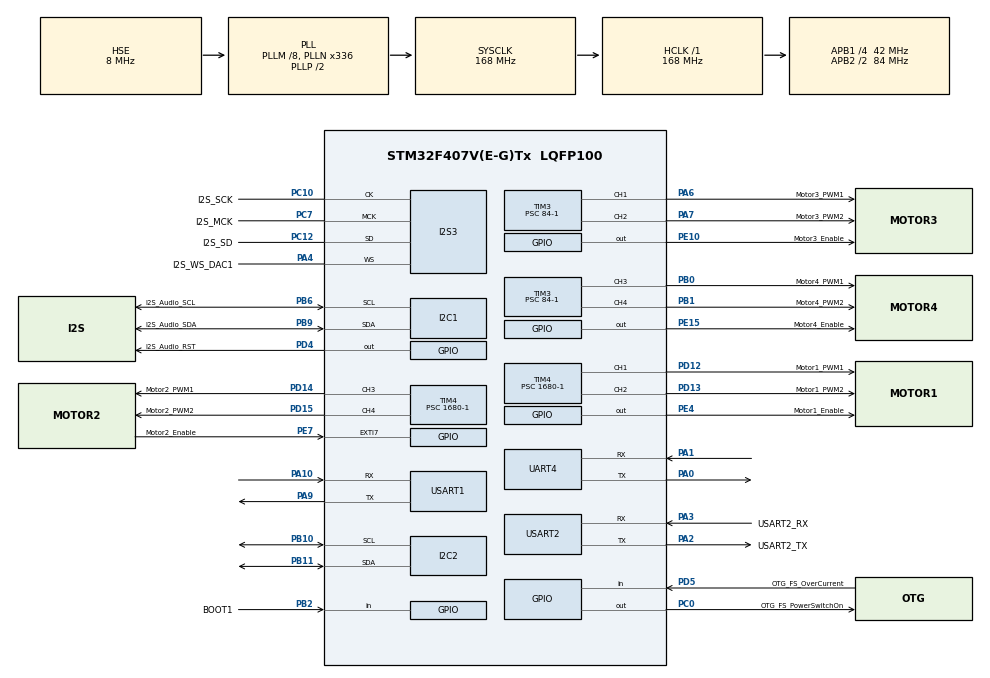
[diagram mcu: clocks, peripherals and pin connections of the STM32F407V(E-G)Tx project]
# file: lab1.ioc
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I2S3.AudioFreq-Half_Duplex_Master=I2S_AUDIOFREQ_96K
I2S3.ErrorAudioFreq=-2.34 %
I2S3.ErrorAudioFreq-Half_Duplex_Master=0.8 %
I2S3.FullDuplexMode=I2S_FULLDUPLEXMODE_DISABLE
I2S3.Instance=SPI$Index
I2S3.RealAudioFreq=93.75 KHz
I2S3.RealAudioFreq-Half_Duplex_Master=96.774 KHz
I2S3.VirtualMode=I2S_MODE_MASTER
Mcu.Family=STM32F4
Mcu.Name=STM32F407V(E-G)Tx
Mcu.Package=LQFP100
NVIC.PriorityGroup=NVIC_PRIORITYGROUP_0
NVIC.UART4_IRQn=true\:0\:0\:false\:false\:true\:true\:true\:true
PA0-WKUP.Mode=Asynchronous
PA0-WKUP.Signal=UART4_TX
PA1.Mode=Asynchronous
PA1.Signal=UART4_RX
PA10.Mode=Asynchronous
PA10.Signal=USART1_RX
PA13.GPIO_Label=SWDIO
PA13.Mode=Serial_Wire
PA13.Signal=SYS_JTMS-SWDIO
PA14.GPIO_Label=SWCLK
PA14.Mode=Serial_Wire
PA14.Signal=SYS_JTCK-SWCLK
PA2.GPIO_Label=USART2_TX
PA2.Mode=Asynchronous
PA2.Signal=USART2_TX
PA3.GPIO_Label=USART2_RX
PA3.Mode=Asynchronous
PA3.Signal=USART2_RX
PA4.GPIO_Label=I2S_WS_DAC1
PA4.GPIO_Mode=GPIO_MODE_AF_PP
PA4.GPIO_PuPd=GPIO_NOPULL
PA4.GPIO_Speed=GPIO_SPEED_FREQ_LOW
PA4.Mode=Half_Duplex_Master
PA4.Signal=I2S3_WS
PA6.GPIO_Label=Motor3_PWM1
PA6.Signal=S_TIM3_CH1
PA7.GPIO_Label=Motor3_PWM2
PA7.Signal=S_TIM3_CH2
PA9.Mode=Asynchronous
PA9.Signal=USART1_TX
PB0.GPIO_Label=Motor4_PWM1
PB0.Signal=S_TIM3_CH3
PB1.GPIO_Label=Motor4_PWM2
PB1.Signal=S_TIM3_CH4
PB10.Mode=I2C
PB10.Signal=I2C2_SCL
PB11.Mode=I2C
PB11.Signal=I2C2_SDA
PB2.GPIO_Label=BOOT1
PB2.GPIO_Mode=GPIO_MODE_INPUT
PB2.GPIO_PuPd=GPIO_NOPULL
PB2.Signal=GPIO_Input
PB6.GPIO_Label=I2S_Audio_SCL
PB6.GPIO_Mode=GPIO_MODE_AF_OD
PB6.GPIO_Pu=GPIO_PULLUP
PB6.GPIO_PuPd=GPIO_NOPULL
PB6.GPIO_Speed=GPIO_SPEED_FREQ_LOW
PB6.Mode=I2C
PB6.Signal=I2C1_SCL
PB9.GPIO_Label=I2S_Audio_SDA
PB9.GPIO_Mode=GPIO_MODE_AF_OD
PB9.GPIO_Pu=GPIO_PULLUP
PB9.GPIO_PuPd=GPIO_NOPULL
PB9.GPIO_Speed=GPIO_SPEED_FREQ_LOW
PB9.Mode=I2C
PB9.Signal=I2C1_SDA
PC0.GPIO_Label=OTG_FS_PowerSwitchOn
PC0.GPIO_PuPd=GPIO_NOPULL
PC0.GPIO_Speed=GPIO_SPEED_FREQ_LOW
PC0.PinState=GPIO_PIN_SET
PC0.Signal=GPIO_Output
PC10.GPIO_Label=I2S_SCK
PC10.GPIO_Mode=GPIO_MODE_AF_PP
PC10.GPIO_PuPd=GPIO_NOPULL
PC10.GPIO_Speed=GPIO_SPEED_FREQ_LOW
PC10.Mode=Half_Duplex_Master
PC10.Signal=I2S3_CK
PC12.GPIO_Label=I2S_SD
PC12.GPIO_Mode=GPIO_MODE_AF_PP
PC12.GPIO_PuPd=GPIO_NOPULL
PC12.GPIO_Speed=GPIO_SPEED_FREQ_LOW
PC12.Mode=Half_Duplex_Master
PC12.Signal=I2S3_SD
PC14-OSC32_IN.GPIO_Label=PC14-OSC32_IN
PC14-OSC32_IN.Mode=LSE-External-Oscillator
PC14-OSC32_IN.Signal=RCC_OSC32_IN
PC15-OSC32_OUT.GPIO_Label=PC15-OSC32_OUT
PC15-OSC32_OUT.Mode=LSE-External-Oscillator
PC15-OSC32_OUT.Signal=RCC_OSC32_OUT
PC7.GPIO_Label=I2S_MCK
PC7.GPIO_Mode=GPIO_MODE_AF_PP
PC7.GPIO_PuPd=GPIO_NOPULL
PC7.GPIO_Speed=GPIO_SPEED_FREQ_LOW
PC7.Mode=Master_Clock_Activated
PC7.Signal=I2S3_MCK
PD12.GPIO_Label=Motor1_PWM1
PD12.Signal=S_TIM4_CH1
PD13.GPIO_Label=Motor1_PWM2
PD13.Signal=S_TIM4_CH2
PD14.GPIO_Label=Motor2_PWM1
PD14.Signal=S_TIM4_CH3
PD15.GPIO_Label=Motor2_PWM2
PD15.Signal=S_TIM4_CH4
PD4.GPIO_Label=I2S_Audio_RST
PD4.GPIO_PuPd=GPIO_NOPULL
PD4.GPIO_Speed=GPIO_SPEED_FREQ_LOW
PD4.Signal=GPIO_Output
PD5.GPIO_Label=OTG_FS_OverCurrent
PD5.GPIO_Mode=GPIO_MODE_INPUT
PD5.GPIO_PuPd=GPIO_NOPULL
PD5.Signal=GPIO_Input
PE10.GPIO_Label=Motor3_Enable
PE10.Signal=GPIO_Output
PE15.GPIO_Label=Motor4_Enable
PE15.Signal=GPIO_Output
PE4.GPIO_Label=Motor1_Enable
PE4.Signal=GPIO_Output
PE7.GPIO_Label=Motor2_Enable
PE7.Signal=GPXTI7
PH0-OSC_IN.GPIO_Label=PH0-OSC_IN
PH0-OSC_IN.Mode=HSE-External-Oscillator
PH0-OSC_IN.Signal=RCC_OSC_IN
PH1-OSC_OUT.GPIO_Label=PH1-OSC_OUT
PH1-OSC_OUT.Mode=HSE-External-Oscillator
PH1-OSC_OUT.Signal=RCC_OSC_OUT
ProjectManager.HeapSize=0x200
ProjectManager.StackSize=0x400
ProjectManager.TargetToolchain=STM32CubeIDE
RCC.48MHZClocksFreq_Value=48000000
RCC.AHBFreq_Value=168000000
RCC.APB1CLKDivider=RCC_HCLK_DIV4
RCC.APB1Freq_Value=42000000
RCC.APB1TimFreq_Value=84000000
RCC.APB2CLKDivider=RCC_HCLK_DIV2
RCC.APB2Freq_Value=84000000
RCC.APB2TimFreq_Value=168000000
RCC.CortexFreq_Value=168000000
RCC.HCLKFreq_Value=168000000
RCC.HSE_VALUE=8000000
RCC.HSI_VALUE=16000000
RCC.PLLM=8
RCC.PLLN=336
RCC.PLLQ=7
RCC.PLLSourceVirtual=RCC_PLLSOURCE_HSE
RCC.SYSCLKFreq_VALUE=168000000
RCC.SYSCLKSource=RCC_SYSCLKSOURCE_PLLCLK
RCC.VCOOutputFreq_Value=336000000
SH.S_TIM3_CH1.0=TIM3_CH1,PWM Generation1 CH1
SH.S_TIM3_CH2.0=TIM3_CH2,PWM Generation2 CH2
SH.S_TIM3_CH3.0=TIM3_CH3,PWM Generation3 CH3
SH.S_TIM3_CH4.0=TIM3_CH4,PWM Generation4 CH4
SH.S_TIM4_CH1.0=TIM4_CH1,PWM Generation1 CH1
SH.S_TIM4_CH2.0=TIM4_CH2,PWM Generation2 CH2
SH.S_TIM4_CH3.0=TIM4_CH3,PWM Generation3 CH3
SH.S_TIM4_CH4.0=TIM4_CH4,PWM Generation4 CH4
TIM3.Channel-PWM\ Generation1\ CH1=TIM_CHANNEL_1
TIM3.Channel-PWM\ Generation2\ CH2=TIM_CHANNEL_2
TIM3.Channel-PWM\ Generation3\ CH3=TIM_CHANNEL_3
TIM3.Channel-PWM\ Generation4\ CH4=TIM_CHANNEL_4
TIM3.Period=100-1
TIM3.Prescaler=84-1
TIM4.Channel-PWM\ Generation1\ CH1=TIM_CHANNEL_1
TIM4.Channel-PWM\ Generation2\ CH2=TIM_CHANNEL_2
TIM4.Channel-PWM\ Generation3\ CH3=TIM_CHANNEL_3
TIM4.Channel-PWM\ Generation4\ CH4=TIM_CHANNEL_4
TIM4.Period=1000-1
TIM4.Prescaler=1680-1
UART4.VirtualMode=Asynchronous
USART1.VirtualMode=VM_ASYNC
USART2.VirtualMode=VM_ASYNC
VP_TIM3_VS_ClockSourceINT.Mode=Internal
VP_TIM4_VS_ClockSourceINT.Mode=Internal
board=STM32F407G-DISC1

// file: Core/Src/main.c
/* USER CODE BEGIN Header */
/**
  ******************************************************************************
  * @file           : main.c
  * @brief          : Main program body
  ******************************************************************************
  * @attention
  *
  * Copyright (c) 2023 STMicroelectronics.
  * All rights reserved.
  *
  * This software is licensed under terms that can be found in the LICENSE file
  * in the root directory of this software component.
  * If no LICENSE file comes with this software, it is provided AS-IS.
  *
  ******************************************************************************
  */
/* USER CODE END Header */
#include "main.h"

I2C_HandleTypeDef hi2c1;
I2C_HandleTypeDef hi2c2;

I2S_HandleTypeDef hi2s3;

TIM_HandleTypeDef htim3;
TIM_HandleTypeDef htim4;

UART_HandleTypeDef huart4;
UART_HandleTypeDef huart1;
UART_HandleTypeDef huart2;

void SystemClock_Config(void);
static void MX_GPIO_Init(void);
static void MX_I2C1_Init(void);
static void MX_I2S3_Init(void);
static void MX_I2C2_Init(void);
static void MX_TIM3_Init(void);
static void MX_TIM4_Init(void);
static void MX_UART4_Init(void);
static void MX_USART1_UART_Init(void);
static void MX_USART2_UART_Init(void);

int main(void)
{

  /* MCU Configuration--------------------------------------------------------*/

  /* Reset of all peripherals, Initializes the Flash interface and the Systick. */
  HAL_Init();

  /* Configure the system clock */
  SystemClock_Config();

  /* Initialize all configured peripherals */
  MX_GPIO_Init();
  MX_I2C1_Init();
  MX_I2S3_Init();
  MX_I2C2_Init();
  MX_TIM3_Init();
  MX_TIM4_Init();
  MX_UART4_Init();
  MX_USART1_UART_Init();
  MX_USART2_UART_Init();
  /* USER CODE BEGIN 2 */
  // Motor Enable Pins set to LOW
  HAL_GPIO_WritePin(Motor1_Enable_GPIO_Port, Motor1_Enable_Pin, GPIO_PIN_SET);
  HAL_GPIO_WritePin(Motor2_Enable_GPIO_Port, Motor2_Enable_Pin, GPIO_PIN_SET);
  /*
  HAL_GPIO_WritePin(Motor3_Enable_GPIO_Port, Motor3_Enable_Pin, GPIO_PIN_SET);
  HAL_GPIO_WritePin(Motor4_Enable_GPIO_Port, Motor4_Enable_Pin, GPIO_PIN_SET);
  */

  // PWM Settings for Motors PWM1 & PWM2 pins
  /*
  TIM3->CCR1 = 0;
  TIM3->CCR2 = 0;
  TIM3->CCR3 = 0;
  TIM3->CCR4 = 0;
  */

  TIM4->CCR1 = 0;
  TIM4->CCR2 = 0;
  TIM4->CCR3 = 0;
  TIM4->CCR4 = 0;

  // PWM Signals is started
  /*
  HAL_TIM_PWM_Start(&htim3, TIM_CHANNEL_1);
  HAL_TIM_PWM_Start(&htim3, TIM_CHANNEL_2);
  HAL_TIM_PWM_Start(&htim3, TIM_CHANNEL_3);
  HAL_TIM_PWM_Start(&htim3, TIM_CHANNEL_4);
  */

  HAL_TIM_PWM_Start(&htim4, TIM_CHANNEL_1);
  HAL_TIM_PWM_Start(&htim4, TIM_CHANNEL_2);
  HAL_TIM_PWM_Start(&htim4, TIM_CHANNEL_3);
  HAL_TIM_PWM_Start(&htim4, TIM_CHANNEL_4);

  // Enable the UART2 RX Interrupt
  __HAL_UART_ENABLE_IT(&huart4, UART_IT_RXNE);	// Enabled UART RX Interrupt
  /* USER CODE END 2 */

  /* Infinite loop */
  while (1)
  {

  }
}

void SystemClock_Config(void)
{
  RCC_OscInitTypeDef RCC_OscInitStruct = {0};
  RCC_ClkInitTypeDef RCC_ClkInitStruct = {0};

  /** Configure the main internal regulator output voltage
  */
  __HAL_RCC_PWR_CLK_ENABLE();
  __HAL_PWR_VOLTAGESCALING_CONFIG(PWR_REGULATOR_VOLTAGE_SCALE1);

  /** Initializes the RCC Oscillators according to the specified parameters
  * in the RCC_OscInitTypeDef structure.
  */
  RCC_OscInitStruct.OscillatorType = RCC_OSCILLATORTYPE_HSE;
  RCC_OscInitStruct.HSEState = RCC_HSE_ON;
  RCC_OscInitStruct.PLL.PLLState = RCC_PLL_ON;
  RCC_OscInitStruct.PLL.PLLSource = RCC_PLLSOURCE_HSE;
  RCC_OscInitStruct.PLL.PLLM = 8;
  RCC_OscInitStruct.PLL.PLLN = 336;
  RCC_OscInitStruct.PLL.PLLP = RCC_PLLP_DIV2;
  RCC_OscInitStruct.PLL.PLLQ = 7;
  if (HAL_RCC_OscConfig(&RCC_OscInitStruct) != HAL_OK)
  {
    Error_Handler();
  }

  /** Initializes the CPU, AHB and APB buses clocks
  */
  RCC_ClkInitStruct.ClockType = RCC_CLOCKTYPE_HCLK|RCC_CLOCKTYPE_SYSCLK
                              |RCC_CLOCKTYPE_PCLK1|RCC_CLOCKTYPE_PCLK2;
  RCC_ClkInitStruct.SYSCLKSource = RCC_SYSCLKSOURCE_PLLCLK;
  RCC_ClkInitStruct.AHBCLKDivider = RCC_SYSCLK_DIV1;
  RCC_ClkInitStruct.APB1CLKDivider = RCC_HCLK_DIV4;
  RCC_ClkInitStruct.APB2CLKDivider = RCC_HCLK_DIV2;

  if (HAL_RCC_ClockConfig(&RCC_ClkInitStruct, FLASH_LATENCY_5) != HAL_OK)
  {
    Error_Handler();
  }
}

static void MX_I2C1_Init(void)
{

  hi2c1.Instance = I2C1;
  hi2c1.Init.ClockSpeed = 100000;
  hi2c1.Init.DutyCycle = I2C_DUTYCYCLE_2;
  hi2c1.Init.OwnAddress1 = 0;
  hi2c1.Init.AddressingMode = I2C_ADDRESSINGMODE_7BIT;
  hi2c1.Init.DualAddressMode = I2C_DUALADDRESS_DISABLE;
  hi2c1.Init.OwnAddress2 = 0;
  hi2c1.Init.GeneralCallMode = I2C_GENERALCALL_DISABLE;
  hi2c1.Init.NoStretchMode = I2C_NOSTRETCH_DISABLE;
  if (HAL_I2C_Init(&hi2c1) != HAL_OK)
  {
    Error_Handler();
  }

}

static void MX_I2C2_Init(void)
{

  hi2c2.Instance = I2C2;
  hi2c2.Init.ClockSpeed = 100000;
  hi2c2.Init.DutyCycle = I2C_DUTYCYCLE_2;
  hi2c2.Init.OwnAddress1 = 0;
  hi2c2.Init.AddressingMode = I2C_ADDRESSINGMODE_7BIT;
  hi2c2.Init.DualAddressMode = I2C_DUALADDRESS_DISABLE;
  hi2c2.Init.OwnAddress2 = 0;
  hi2c2.Init.GeneralCallMode = I2C_GENERALCALL_DISABLE;
  hi2c2.Init.NoStretchMode = I2C_NOSTRETCH_DISABLE;
  if (HAL_I2C_Init(&hi2c2) != HAL_OK)
  {
    Error_Handler();
  }

}

static void MX_I2S3_Init(void)
{

  hi2s3.Instance = SPI3;
  hi2s3.Init.Mode = I2S_MODE_MASTER_TX;
  hi2s3.Init.Standard = I2S_STANDARD_PHILIPS;
  hi2s3.Init.DataFormat = I2S_DATAFORMAT_16B;
  hi2s3.Init.MCLKOutput = I2S_MCLKOUTPUT_ENABLE;
  hi2s3.Init.AudioFreq = I2S_AUDIOFREQ_96K;
  hi2s3.Init.CPOL = I2S_CPOL_LOW;
  hi2s3.Init.ClockSource = I2S_CLOCK_PLL;
  hi2s3.Init.FullDuplexMode = I2S_FULLDUPLEXMODE_DISABLE;
  if (HAL_I2S_Init(&hi2s3) != HAL_OK)
  {
    Error_Handler();
  }

}

static void MX_TIM3_Init(void)
{

  TIM_ClockConfigTypeDef sClockSourceConfig = {0};
  TIM_MasterConfigTypeDef sMasterConfig = {0};
  TIM_OC_InitTypeDef sConfigOC = {0};

  htim3.Instance = TIM3;
  htim3.Init.Prescaler = 84-1;
  htim3.Init.CounterMode = TIM_COUNTERMODE_UP;
  htim3.Init.Period = 100-1;
  htim3.Init.ClockDivision = TIM_CLOCKDIVISION_DIV1;
  htim3.Init.AutoReloadPreload = TIM_AUTORELOAD_PRELOAD_DISABLE;
  if (HAL_TIM_Base_Init(&htim3) != HAL_OK)
  {
    Error_Handler();
  }
  sClockSourceConfig.ClockSource = TIM_CLOCKSOURCE_INTERNAL;
  if (HAL_TIM_ConfigClockSource(&htim3, &sClockSourceConfig) != HAL_OK)
  {
    Error_Handler();
  }
  if (HAL_TIM_PWM_Init(&htim3) != HAL_OK)
  {
    Error_Handler();
  }
  sMasterConfig.MasterOutputTrigger = TIM_TRGO_RESET;
  sMasterConfig.MasterSlaveMode = TIM_MASTERSLAVEMODE_DISABLE;
  if (HAL_TIMEx_MasterConfigSynchronization(&htim3, &sMasterConfig) != HAL_OK)
  {
    Error_Handler();
  }
  sConfigOC.OCMode = TIM_OCMODE_PWM1;
  sConfigOC.Pulse = 0;
  sConfigOC.OCPolarity = TIM_OCPOLARITY_HIGH;
  sConfigOC.OCFastMode = TIM_OCFAST_DISABLE;
  if (HAL_TIM_PWM_ConfigChannel(&htim3, &sConfigOC, TIM_CHANNEL_1) != HAL_OK)
  {
    Error_Handler();
  }
  if (HAL_TIM_PWM_ConfigChannel(&htim3, &sConfigOC, TIM_CHANNEL_2) != HAL_OK)
  {
    Error_Handler();
  }
  if (HAL_TIM_PWM_ConfigChannel(&htim3, &sConfigOC, TIM_CHANNEL_3) != HAL_OK)
  {
    Error_Handler();
  }
  if (HAL_TIM_PWM_ConfigChannel(&htim3, &sConfigOC, TIM_CHANNEL_4) != HAL_OK)
  {
    Error_Handler();
  }
  HAL_TIM_MspPostInit(&htim3);

}

static void MX_TIM4_Init(void)
{

  TIM_ClockConfigTypeDef sClockSourceConfig = {0};
  TIM_MasterConfigTypeDef sMasterConfig = {0};
  TIM_OC_InitTypeDef sConfigOC = {0};

  htim4.Instance = TIM4;
  htim4.Init.Prescaler = 1680-1;
  htim4.Init.CounterMode = TIM_COUNTERMODE_UP;
  htim4.Init.Period = 1000-1;
  htim4.Init.ClockDivision = TIM_CLOCKDIVISION_DIV1;
  htim4.Init.AutoReloadPreload = TIM_AUTORELOAD_PRELOAD_DISABLE;
  if (HAL_TIM_Base_Init(&htim4) != HAL_OK)
  {
    Error_Handler();
  }
  sClockSourceConfig.ClockSource = TIM_CLOCKSOURCE_INTERNAL;
  if (HAL_TIM_ConfigClockSource(&htim4, &sClockSourceConfig) != HAL_OK)
  {
    Error_Handler();
  }
  if (HAL_TIM_PWM_Init(&htim4) != HAL_OK)
  {
    Error_Handler();
  }
  sMasterConfig.MasterOutputTrigger = TIM_TRGO_RESET;
  sMasterConfig.MasterSlaveMode = TIM_MASTERSLAVEMODE_DISABLE;
  if (HAL_TIMEx_MasterConfigSynchronization(&htim4, &sMasterConfig) != HAL_OK)
  {
    Error_Handler();
  }
  sConfigOC.OCMode = TIM_OCMODE_PWM1;
  sConfigOC.Pulse = 0;
  sConfigOC.OCPolarity = TIM_OCPOLARITY_HIGH;
  sConfigOC.OCFastMode = TIM_OCFAST_DISABLE;
  if (HAL_TIM_PWM_ConfigChannel(&htim4, &sConfigOC, TIM_CHANNEL_1) != HAL_OK)
  {
    Error_Handler();
  }
  if (HAL_TIM_PWM_ConfigChannel(&htim4, &sConfigOC, TIM_CHANNEL_2) != HAL_OK)
  {
    Error_Handler();
  }
  if (HAL_TIM_PWM_ConfigChannel(&htim4, &sConfigOC, TIM_CHANNEL_3) != HAL_OK)
  {
    Error_Handler();
  }
  if (HAL_TIM_PWM_ConfigChannel(&htim4, &sConfigOC, TIM_CHANNEL_4) != HAL_OK)
  {
    Error_Handler();
  }
  HAL_TIM_MspPostInit(&htim4);

}

static void MX_UART4_Init(void)
{

  huart4.Instance = UART4;
  huart4.Init.BaudRate = 115200;
  huart4.Init.WordLength = UART_WORDLENGTH_8B;
  huart4.Init.StopBits = UART_STOPBITS_1;
  huart4.Init.Parity = UART_PARITY_NONE;
  huart4.Init.Mode = UART_MODE_TX_RX;
  huart4.Init.HwFlowCtl = UART_HWCONTROL_NONE;
  huart4.Init.OverSampling = UART_OVERSAMPLING_16;
  if (HAL_UART_Init(&huart4) != HAL_OK)
  {
    Error_Handler();
  }

}

static void MX_USART1_UART_Init(void)
{

  huart1.Instance = USART1;
  huart1.Init.BaudRate = 115200;
  huart1.Init.WordLength = UART_WORDLENGTH_8B;
  huart1.Init.StopBits = UART_STOPBITS_1;
  huart1.Init.Parity = UART_PARITY_NONE;
  huart1.Init.Mode = UART_MODE_TX_RX;
  huart1.Init.HwFlowCtl = UART_HWCONTROL_NONE;
  huart1.Init.OverSampling = UART_OVERSAMPLING_16;
  if (HAL_UART_Init(&huart1) != HAL_OK)
  {
    Error_Handler();
  }

}

static void MX_USART2_UART_Init(void)
{

  huart2.Instance = USART2;
  huart2.Init.BaudRate = 115200;
  huart2.Init.WordLength = UART_WORDLENGTH_8B;
  huart2.Init.StopBits = UART_STOPBITS_1;
  huart2.Init.Parity = UART_PARITY_NONE;
  huart2.Init.Mode = UART_MODE_TX_RX;
  huart2.Init.HwFlowCtl = UART_HWCONTROL_NONE;
  huart2.Init.OverSampling = UART_OVERSAMPLING_16;
  if (HAL_UART_Init(&huart2) != HAL_OK)
  {
    Error_Handler();
  }

}

static void MX_GPIO_Init(void)
{
  GPIO_InitTypeDef GPIO_InitStruct = {0};

  /* GPIO Ports Clock Enable */
  __HAL_RCC_GPIOE_CLK_ENABLE();
  __HAL_RCC_GPIOC_CLK_ENABLE();
  __HAL_RCC_GPIOH_CLK_ENABLE();
  __HAL_RCC_GPIOA_CLK_ENABLE();
  __HAL_RCC_GPIOB_CLK_ENABLE();
  __HAL_RCC_GPIOD_CLK_ENABLE();

  /*Configure GPIO pin Output Level */
  HAL_GPIO_WritePin(GPIOE, Motor1_Enable_Pin|Motor3_Enable_Pin|Motor4_Enable_Pin, GPIO_PIN_RESET);

  /*Configure GPIO pin Output Level */
  HAL_GPIO_WritePin(OTG_FS_PowerSwitchOn_GPIO_Port, OTG_FS_PowerSwitchOn_Pin, GPIO_PIN_SET);

  /*Configure GPIO pin Output Level */
  HAL_GPIO_WritePin(I2S_Audio_RST_GPIO_Port, I2S_Audio_RST_Pin, GPIO_PIN_RESET);

  /*Configure GPIO pins : Motor1_Enable_Pin Motor3_Enable_Pin Motor4_Enable_Pin */
  GPIO_InitStruct.Pin = Motor1_Enable_Pin|Motor3_Enable_Pin|Motor4_Enable_Pin;
  GPIO_InitStruct.Mode = GPIO_MODE_OUTPUT_PP;
  GPIO_InitStruct.Pull = GPIO_NOPULL;
  GPIO_InitStruct.Speed = GPIO_SPEED_FREQ_LOW;
  HAL_GPIO_Init(GPIOE, &GPIO_InitStruct);

  /*Configure GPIO pin : OTG_FS_PowerSwitchOn_Pin */
  GPIO_InitStruct.Pin = OTG_FS_PowerSwitchOn_Pin;
  GPIO_InitStruct.Mode = GPIO_MODE_OUTPUT_PP;
  GPIO_InitStruct.Pull = GPIO_NOPULL;
  GPIO_InitStruct.Speed = GPIO_SPEED_FREQ_LOW;
  HAL_GPIO_Init(OTG_FS_PowerSwitchOn_GPIO_Port, &GPIO_InitStruct);

  /*Configure GPIO pin : BOOT1_Pin */
  GPIO_InitStruct.Pin = BOOT1_Pin;
  GPIO_InitStruct.Mode = GPIO_MODE_INPUT;
  GPIO_InitStruct.Pull = GPIO_NOPULL;
  HAL_GPIO_Init(BOOT1_GPIO_Port, &GPIO_InitStruct);

  /*Configure GPIO pin : Motor2_Enable_Pin */
  GPIO_InitStruct.Pin = Motor2_Enable_Pin;
  GPIO_InitStruct.Mode = GPIO_MODE_IT_RISING;
  GPIO_InitStruct.Pull = GPIO_NOPULL;
  HAL_GPIO_Init(Motor2_Enable_GPIO_Port, &GPIO_InitStruct);

  /*Configure GPIO pin : I2S_Audio_RST_Pin */
  GPIO_InitStruct.Pin = I2S_Audio_RST_Pin;
  GPIO_InitStruct.Mode = GPIO_MODE_OUTPUT_PP;
  GPIO_InitStruct.Pull = GPIO_NOPULL;
  GPIO_InitStruct.Speed = GPIO_SPEED_FREQ_LOW;
  HAL_GPIO_Init(I2S_Audio_RST_GPIO_Port, &GPIO_InitStruct);

  /*Configure GPIO pin : OTG_FS_OverCurrent_Pin */
  GPIO_InitStruct.Pin = OTG_FS_OverCurrent_Pin;
  GPIO_InitStruct.Mode = GPIO_MODE_INPUT;
  GPIO_InitStruct.Pull = GPIO_NOPULL;
  HAL_GPIO_Init(OTG_FS_OverCurrent_GPIO_Port, &GPIO_InitStruct);

}

void Error_Handler(void)
{
  __disable_irq();
  while (1)
  {
  }
}
